# LPC12D27 register map
File version: 3
Registers are 32-bit, read-write, reset 0x0 unless marked. A register's access mark holds for its fields unless they carry their own. Offsets are from the block's base; [hi:lo] are bit positions; {n}, {i} and the like mark numbered series; 'fields as' and 'values as' point back to an identical list.

## IOCON — Product name title=UM10441 Chapter title=LPC122x I/O configuration (IOCONFIG) Modification date=8/18/2011 Major revision=2 Minor revision=0
Base 0x40044000
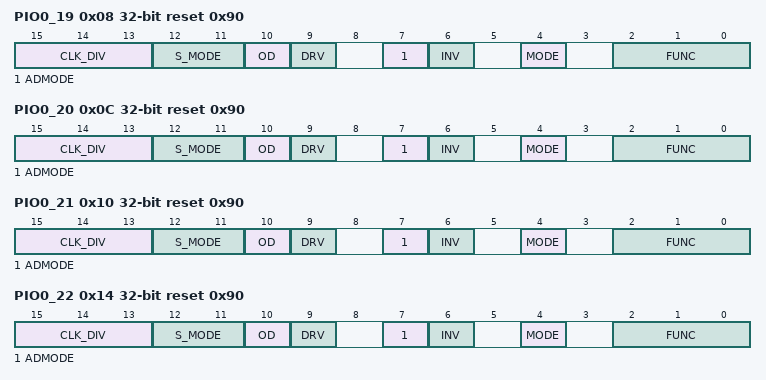
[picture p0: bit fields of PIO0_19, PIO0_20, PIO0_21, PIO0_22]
0x08 PIO0_19 reset 0x90 — Configures pin PIO0_19/ACMP0_I0/CT32B0_1.
  [15:13] CLK_DIV — Select peripheral clock divider for input filter sampling clock.
    {v}=IOCONFIGCLKDIV{v}_ (v=0..6)
  [12:11] S_MODE — Sample mode
    0=BYPASS_INPUT_FILTER_; 1=ONEFILTERCLOCK (Input pulses shorter than one filter clock are rejected.); 2=TWOFILTERCLOCKS (Input pulses shorter than two filter clocks are rejected.); 3=THREEFILTERCLOCKS (Input pulses shorter than three filter clocks are rejected.)
  [10] OD — Open-drain mode.
    0=OPEN_DRAIN_MODE_DISA (Open-drain mode disabled.); 1=OPEN_DRAIN_MODE_ENAB (Open-drain mode enabled.)
  [9] DRV — Drive current mode (Normal-drive pin).
    0=HIGH_MODE_CURRENT_SE (High mode current selected.); 1=LOW_MODE_CURRENT_SEL (Low mode current selected.)
  [7] ADMODE — Analog/Digital mode
    0=ANALOG_MODE_ENABLED_; 1=DIGITAL_MODE_ENABLED
  [6] INV — Invert input
    0=INPUT_NOT_INVERTED_; 1=INPUT_INVERTED_
  [4] MODE — Selects function mode (on-chip pull-up resistor control).
    0=INACTIVE_PULL_UP_RE (Inactive (pull-up resistor not enabled).); 1=PULL_UP_RESISTOR_ENA (Pull-up resistor enabled.)
  [2:0] FUNC — Selects pin function.
    0=SELECTS_FUNCTION_PIO (Selects function PIO0_19.); 1=RESERVED_DO_NOT_USE; 2=ACMP (Select function ACMP0_I0.); 3=CT32 (Select function CT32B0_CAP1.); 4=CT32 (Select function CT32B0_MAT1.)
0x0C PIO0_20 reset 0x90 — Configures pin PIO0_20/ACMP0_I1/CT32B0_2.
  [15:13] CLK_DIV — Select peripheral clock divider for input filter sampling clock.
    {v}=IOCONFIGCLKDIV{v}_ (v=0..6)
  [12:11] S_MODE — Sample mode
    values as PIO0_19.S_MODE
  [10] OD — Open-drain mode.
    values as PIO0_19.OD
  [9] DRV — Drive current mode (Normal-drive pin).
    values as PIO0_19.DRV
  [7] ADMODE — Analog/Digital mode
    0=ANALOG_MODE_ENABLED_; 1=DIGITAL_MODE_ENABLED
  [6] INV — Invert input
    0=INPUT_NOT_INVERTED_; 1=INPUT_INVERTED_
  [4] MODE — Selects function mode (on-chip pull-up resistor control).
    values as PIO0_19.MODE
  [2:0] FUNC — Selects pin function.
    0=SELECTS_FUNCTION_PIO (Selects function PIO0_20.); 1=RESERVED_DO_NOT_USE; 2=ACMP (Select function ACMP0_I1.); 3=CT32 (Select function CT32B0_CAP2.); 4=CT32 (Select function CT32B0_MAT2.)
0x10 PIO0_21 reset 0x90 — Configures pin PIO0_21/ACMP0_I2/CT32B0_3.
  [15:13] CLK_DIV — Select peripheral clock divider for input filter sampling clock.
    {v}=IOCONFIGCLKDIV{v}_ (v=0..6)
  [12:11] S_MODE — Sample mode
    values as PIO0_19.S_MODE
  [10] OD — Open-drain mode.
    values as PIO0_19.OD
  [9] DRV — Drive current mode (Normal-drive pin).
    values as PIO0_19.DRV
  [7] ADMODE — Analog/Digital mode
    0=ANALOG_MODE_ENABLED_; 1=DIGITAL_MODE_ENABLED
  [6] INV — Invert input
    0=INPUT_NOT_INVERTED_; 1=INPUT_INVERTED_
  [4] MODE — Selects function mode (on-chip pull-up resistor control).
    values as PIO0_19.MODE
  [2:0] FUNC — Selects pin function.
    0=SELECTS_FUNCTION_PIO (Selects function PIO0_21.); 1=RESERVED_DO_NOT_USE; 2=ACMP (Select function ACMP0_I2.); 3=CT32 (Select function CT32B0_CAP3.); 4=CT32 (Select function CT32B0_MAT3.)
0x14 PIO0_22 reset 0x90 — Configures pin PIO0_22/ACMP0_I3.
  [15:13] CLK_DIV — Select peripheral clock divider for input filter sampling clock.
    {v}=IOCONFIGCLKDIV{v}_ (v=0..6)
  [12:11] S_MODE — Sample mode
    values as PIO0_19.S_MODE
  [10] OD — Open-drain mode.
    values as PIO0_19.OD
  [9] DRV — Drive current mode (Normal-drive pin).
    values as PIO0_19.DRV
  [7] ADMODE — Analog/Digital mode
    0=ANALOG_MODE_ENABLED_; 1=DIGITAL_MODE_ENABLED
  [6] INV — Invert input
    0=INPUT_NOT_INVERTED_; 1=INPUT_INVERTED_
  [4] MODE — Selects function mode (on-chip pull-up resistor control).
    values as PIO0_19.MODE
  [2:0] FUNC — Selects pin function.
    0=SELECTS_FUNCTION_PIO (Selects function PIO0_22.); 1=RESERVED_DO_NOT_USE; 2=ACMP (Select function ACMP0_I3.)
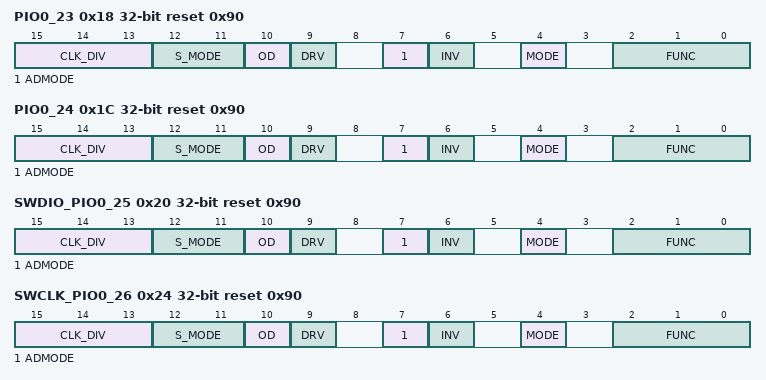
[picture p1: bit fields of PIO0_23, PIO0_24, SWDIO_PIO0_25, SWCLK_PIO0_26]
0x18 PIO0_23 reset 0x90 — Configures pin PIO0_23/ACMP1_I0/CT32B1_0.
  [15:13] CLK_DIV — Select peripheral clock divider for input filter sampling clock.
    {v}=IOCONFIGCLKDIV{v}_ (v=0..6)
  [12:11] S_MODE — Sample mode
    values as PIO0_19.S_MODE
  [10] OD — Open-drain mode.
    values as PIO0_19.OD
  [9] DRV — Drive current mode (Normal-drive pin).
    values as PIO0_19.DRV
  [7] ADMODE — Analog/Digital mode
    0=ANALOG_MODE_ENABLED_; 1=DIGITAL_MODE_ENABLED
  [6] INV — Invert input
    0=INPUT_NOT_INVERTED_; 1=INPUT_INVERTED_
  [4] MODE — Selects function mode (on-chip pull-up resistor control).
    values as PIO0_19.MODE
  [2:0] FUNC — Selects pin function.
    0=SELECTS_FUNCTION_PIO (Selects function PIO0_23.); 1=RESERVED_DO_NOT_USE; 2=ACMP (Select function ACMP1_I0.); 3=CT32 (Select function CT32B1_CAP0.); 4=CT32 (Select function CT32B1_MAT0.)
0x1C PIO0_24 reset 0x90 — Configures pin PIO0_24/ACMP1_I1/CT32B1_1.
  [15:13] CLK_DIV — Select peripheral clock divider for input filter sampling clock.
    {v}=IOCONFIGCLKDIV{v}_ (v=0..6)
  [12:11] S_MODE — Sample mode
    values as PIO0_19.S_MODE
  [10] OD — Open-drain mode.
    values as PIO0_19.OD
  [9] DRV — Drive current mode (Normal-drive pin).
    values as PIO0_19.DRV
  [7] ADMODE — Analog/Digital mode
    0=ANALOG_MODE_ENABLED_; 1=DIGITAL_MODE_ENABLED
  [6] INV — Invert input
    0=INPUT_NOT_INVERTED_; 1=INPUT_INVERTED_
  [4] MODE — Selects function mode (on-chip pull-up resistor control).
    values as PIO0_19.MODE
  [2:0] FUNC — Selects pin function.
    0=SELECTS_FUNCTION_PIO (Selects function PIO0_24.); 1=RESERVED_DO_NOT_USE; 2=ACMP (Select function ACMP1_I1.); 3=CT32 (Select function CT32B1_CAP1.); 4=CT32 (Select function CT32B1_MAT1.)
0x20 SWDIO_PIO0_25 reset 0x90 — Configures pin SWDIO/ACMP1_I2/ CT32B1_2/PIO0_25.
  [15:13] CLK_DIV — Select peripheral clock divider for input filter sampling clock.
    {v}=IOCONFIGCLKDIV{v}_ (v=0..6)
  [12:11] S_MODE — Sample mode
    values as PIO0_19.S_MODE
  [10] OD — Open-drain mode.
    values as PIO0_19.OD
  [9] DRV — Drive current mode (Normal-drive pin).
    values as PIO0_19.DRV
  [7] ADMODE — Analog/Digital mode
    0=ANALOG_MODE_ENABLED_; 1=DIGITAL_MODE_ENABLED
  [6] INV — Invert input
    0=INPUT_NOT_INVERTED_; 1=INPUT_INVERTED_
  [4] MODE — Selects function mode (on-chip pull-up resistor control).
    values as PIO0_19.MODE
  [2:0] FUNC — Selects pin function.
    0=SELECTS_FUNCTION_SWD (Selects function SWDIO.); 1=RESERVED_DO_NOT_USE; 2=ACMP (Select function ACMP1_I2.); 3=CT32 (Select function CT32B1_CAP2.); 4=CT32 (Select function CT32B1_MAT2.); 6=PIO0 (Select function PIO0_25.)
0x24 SWCLK_PIO0_26 reset 0x90 — Configures pin SWCLK/PIO0_26/ACMP1_I3/ CT32B1_3/PIO0_26
  [15:13] CLK_DIV — Select peripheral clock divider for input filter sampling clock.
    {v}=IOCONFIGCLKDIV{v}_ (v=0..6)
  [12:11] S_MODE — Sample mode
    values as PIO0_19.S_MODE
  [10] OD — Open-drain mode.
    values as PIO0_19.OD
  [9] DRV — Drive current mode (Normal-drive pin).
    values as PIO0_19.DRV
  [7] ADMODE — Analog/Digital mode
    0=ANALOG_MODE_ENABLED_; 1=DIGITAL_MODE_ENABLED
  [6] INV — Invert input
    0=INPUT_NOT_INVERTED_; 1=INPUT_INVERTED_
  [4] MODE — Selects function mode (on-chip pull-up resistor control).
    values as PIO0_19.MODE
  [2:0] FUNC — Selects pin function.
    0=SELECTS_FUNCTION_SWC (Selects function SWCLK.); 1=RESERVED_DO_NOT_USE; 2=ACMP (Select function ACMP1_I3.); 3=CT32 (Select function CT32B1_CAP3.); 4=CT32 (Select function CT32B1_MAT3.); 6=PIO0 (Select function PIO0_26.)
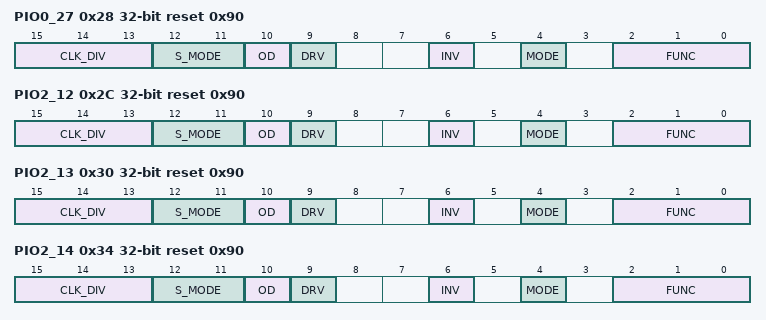
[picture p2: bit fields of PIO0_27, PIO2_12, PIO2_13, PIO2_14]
0x28 PIO0_27 reset 0x90 — Configures pin PIO0_27/ACMP0_O.
  [15:13] CLK_DIV — Select peripheral clock divider for input filter sampling clock.
    {v}=IOCONFIGCLKDIV{v}_ (v=0..6)
  [12:11] S_MODE — Sample mode
    values as PIO0_19.S_MODE
  [10] OD — Open-drain mode.
    values as PIO0_19.OD
  [9] DRV — Drive current mode (High-drive pin).
    0=LOW_MODE_CURRENT_SEL (Low mode current selected.); 1=HIGH_MODE_CURRENT_SE (High mode current selected.)
  [6] INV — Invert input
    0=INPUT_NOT_INVERTED_; 1=INPUT_INVERTED_
  [4] MODE — Selects function mode (on-chip pull-up resistor control).
    values as PIO0_19.MODE
  [2:0] FUNC — Selects pin function.
    0=SELECTS_FUNCTION_PIO (Selects function PIO0_26.); 1=RESERVED_DO_NOT_USE; 2=ACMP (Select function ACMP0_O.)
0x2C PIO2_12 reset 0x90 — Configures pin PIO2_12/RXD1.
  [15:13] CLK_DIV — Select peripheral clock divider for input filter sampling clock.
    {v}=IOCONFIGCLKDIV{v}_ (v=0..6)
  [12:11] S_MODE — Sample mode
    values as PIO0_19.S_MODE
  [10] OD — Open-drain mode.
    values as PIO0_19.OD
  [9] DRV — Drive current mode (Normal-drive pin).
    values as PIO0_27.DRV
  [6] INV — Invert input
    0=INPUT_NOT_INVERTED_; 1=INPUT_INVERTED_
  [4] MODE — Selects function mode (on-chip pull-up resistor control).
    values as PIO0_19.MODE
  [2:0] FUNC — Selects pin function.
    0=SELECTS_FUNCTION_PIO (Selects function PIO2_12.); 1=RESERVED_DO_NOT_USE; 3=SELECTS_FUNCTION_RXD (Selects function RXD1.)
0x30 PIO2_13 reset 0x90 — Configures pin PIO2_13/TXD1.
  [15:13] CLK_DIV — Select peripheral clock divider for input filter sampling clock.
    {v}=IOCONFIGCLKDIV{v}_ (v=0..6)
  [12:11] S_MODE — Sample mode
    values as PIO0_19.S_MODE
  [10] OD — Open-drain mode.
    values as PIO0_19.OD
  [9] DRV — Drive current mode (Normal-drive pin).
    values as PIO0_27.DRV
  [6] INV — Invert input
    0=INPUT_NOT_INVERTED_; 1=INPUT_INVERTED_
  [4] MODE — Selects function mode (on-chip pull-up resistor control).
    values as PIO0_19.MODE
  [2:0] FUNC — Selects pin function.
    0=SELECTS_FUNCTION_PIO (Selects function PIO2_13.); 1=RESERVED_DO_NOT_USE; 3=TXD1 (Select function TXD1.)
0x34 PIO2_14 reset 0x90 — Configures pin PIO2_14.
  [15:13] CLK_DIV — Select peripheral clock divider for input filter sampling clock.
    {v}=IOCONFIGCLKDIV{v}_ (v=0..6)
  [12:11] S_MODE — Sample mode
    values as PIO0_19.S_MODE
  [10] OD — Open-drain mode.
    values as PIO0_19.OD
  [9] DRV — Drive current mode (Normal-drive pin).
    values as PIO0_27.DRV
  [6] INV — Invert input
    0=INPUT_NOT_INVERTED_; 1=INPUT_INVERTED_
  [4] MODE — Selects function mode (on-chip pull-up resistor control).
    values as PIO0_19.MODE
  [2:0] FUNC — Selects pin function.
    0=SELECTS_FUNCTION_PIO (Selects function PIO2_14.)
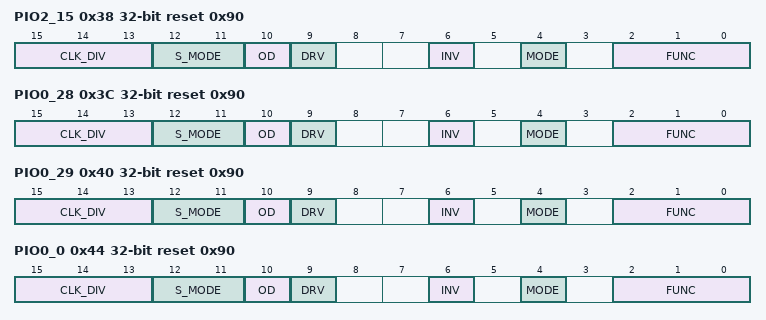
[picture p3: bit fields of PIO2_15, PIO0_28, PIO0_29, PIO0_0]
0x38 PIO2_15 reset 0x90 — Configures pin PIO2_15.
  [15:13] CLK_DIV — Select peripheral clock divider for input filter sampling clock.
    {v}=IOCONFIGCLKDIV{v}_ (v=0..6)
  [12:11] S_MODE — Sample mode
    values as PIO0_19.S_MODE
  [10] OD — Open-drain mode.
    values as PIO0_19.OD
  [9] DRV — Drive current mode (Normal-drive pin).
    values as PIO0_27.DRV
  [6] INV — Invert input
    0=INPUT_NOT_INVERTED_; 1=INPUT_INVERTED_
  [4] MODE — Selects function mode (on-chip pull-up resistor control).
    values as PIO0_19.MODE
  [2:0] FUNC — Selects pin function.
    0=SELECTS_FUNCTION_PIO (Selects function PIO2_15.)
0x3C PIO0_28 reset 0x90 — Configures pin PIO0_28/ACMP1_O/CT16B0_0.
  [15:13] CLK_DIV — Select peripheral clock divider for input filter sampling clock.
    {v}=IOCONFIGCLKDIV{v}_ (v=0..6)
  [12:11] S_MODE — Sample mode
    values as PIO0_19.S_MODE
  [10] OD — Open-drain mode.
    values as PIO0_19.OD
  [9] DRV — Drive current mode (High-drive pin).
    values as PIO0_27.DRV
  [6] INV — Invert input
    0=INPUT_NOT_INVERTED_; 1=INPUT_INVERTED_
  [4] MODE — Selects function mode (on-chip pull-up resistor control).
    values as PIO0_19.MODE
  [2:0] FUNC — Selects pin function.
    0=SELECTS_FUNCTION_PIO (Selects function PIO0_28.); 1=RESERVED_DO_NOT_USE; 2=ACMP (Select function ACMP1_O.); 3=CT16 (Select function CT16B0_CAP0.); 4=CT16 (Select function CT16B0_MAT0.)
0x40 PIO0_29 reset 0x90 — Configures pin PIO0_29/ROSC/CT16B0_1.
  [15:13] CLK_DIV — Select peripheral clock divider for input filter sampling clock.
    {v}=IOCONFIGCLKDIV{v}_ (v=0..6)
  [12:11] S_MODE — Sample mode
    values as PIO0_19.S_MODE
  [10] OD — Open-drain mode.
    values as PIO0_19.OD
  [9] DRV — Drive current mode (High-drive pin).
    values as PIO0_27.DRV
  [6] INV — Invert input
    0=INPUT_NOT_INVERTED_; 1=INPUT_INVERTED_
  [4] MODE — Selects function mode (on-chip pull-up resistor control).
    values as PIO0_19.MODE
  [2:0] FUNC — Selects pin function.
    0=SELECTS_FUNCTION_PIO (Selects function PIO0_29.); 1=RESERVED_DO_NOT_USE; 2=ROSC (Select function ROSC.); 3=CT16 (Select function CT16B0_CAP1.); 4=CT16 (Select function CT16B0_MAT1.)
0x44 PIO0_0 reset 0x90 — Configures pin PIO0_0/ RTS0.
  [15:13] CLK_DIV — Select peripheral clock divider for input filter sampling clock.
    {v}=IOCONFIGCLKDIV{v}_ (v=0..6)
  [12:11] S_MODE — Sample mode
    values as PIO0_19.S_MODE
  [10] OD — Open-drain mode.
    values as PIO0_19.OD
  [9] DRV — Drive current mode (Normal-drive pin).
    values as PIO0_27.DRV
  [6] INV — Invert input
    0=INPUT_NOT_INVERTED_; 1=INPUT_INVERTED_
  [4] MODE — Selects function mode (on-chip pull-up resistor control).
    values as PIO0_19.MODE
  [2:0] FUNC — Selects pin function.
    0=SELECTS_FUNCTION_PIO (Selects function PIO0_0.); 1=RESERVED_DO_NOT_USE; 2=RTS0 (Select function RTS0.)
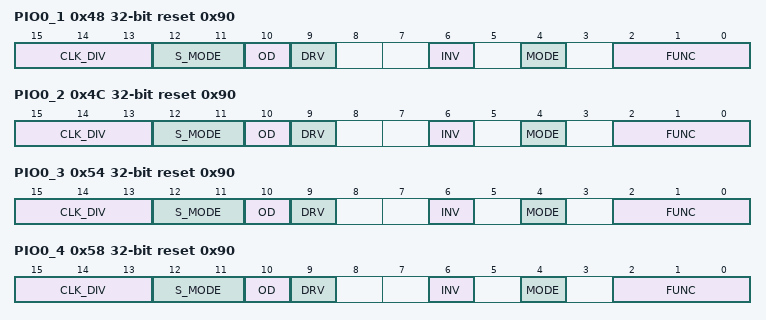
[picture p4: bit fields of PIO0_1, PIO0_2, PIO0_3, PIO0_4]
0x48 PIO0_1 reset 0x90 — Configures pin PIO0_1CT32B0_0/RXD0.
  [15:13] CLK_DIV — Select peripheral clock divider for input filter sampling clock.
    {v}=IOCONFIGCLKDIV{v}_ (v=0..6)
  [12:11] S_MODE — Sample mode
    values as PIO0_19.S_MODE
  [10] OD — Open-drain mode.
    values as PIO0_19.OD
  [9] DRV — Drive current mode (Normal-drive pin).
    values as PIO0_27.DRV
  [6] INV — Invert input
    0=INPUT_NOT_INVERTED_; 1=INPUT_INVERTED_
  [4] MODE — Selects function mode (on-chip pull-up resistor control).
    values as PIO0_19.MODE
  [2:0] FUNC — Selects pin function.
    0=SELECTS_FUNCTION_PIO (Selects function PIO0_1.); 1=RESERVED_DO_NOT_USE; 2=RXD0 (Select function RXD0.); 3=CT32 (Select function CT32B0_CAP0.); 4=CT32 (Select function CT32B0_MAT0.)
0x4C PIO0_2 reset 0x90 — Configures pin PIO0_2/TXD0/CT32B0_1.
  [15:13] CLK_DIV — Select peripheral clock divider for input filter sampling clock.
    {v}=IOCONFIGCLKDIV{v}_ (v=0..6)
  [12:11] S_MODE — Sample mode
    values as PIO0_19.S_MODE
  [10] OD — Open-drain mode.
    values as PIO0_19.OD
  [9] DRV — Drive current mode (Normal-drive pin).
    values as PIO0_27.DRV
  [6] INV — Invert input
    0=INPUT_NOT_INVERTED_; 1=INPUT_INVERTED_
  [4] MODE — Selects function mode (on-chip pull-up resistor control).
    values as PIO0_19.MODE
  [2:0] FUNC — Selects pin function.
    0=SELECTS_FUNCTION_PIO (Selects function PIO0_2.); 1=RESERVED_DO_NOT_USE; 2=TXD0 (Select function TXD0.); 3=CT32 (Select function CT32B0_CAP1.); 4=CT32 (Select function CT32B0_MAT1.)
0x54 PIO0_3 reset 0x90 — Configures pin PIO0_3/DTR0/CT32B0_2.
  [15:13] CLK_DIV — Select peripheral clock divider for input filter sampling clock.
    {v}=IOCONFIGCLKDIV{v}_ (v=0..6)
  [12:11] S_MODE — Sample mode
    values as PIO0_19.S_MODE
  [10] OD — Open-drain mode.
    values as PIO0_19.OD
  [9] DRV — Drive current mode (Normal-drive pin).
    values as PIO0_27.DRV
  [6] INV — Invert input
    0=INPUT_NOT_INVERTED_; 1=INPUT_INVERTED_
  [4] MODE — Selects function mode (on-chip pull-up resistor control).
    values as PIO0_19.MODE
  [2:0] FUNC — Selects pin function.
    0=SELECTS_FUNCTION_PIO (Selects function PIO0_3.); 1=RESERVED_DO_NOT_USE; 2=DTR0 (Select function DTR0.); 3=CT32 (Select function CT32B0_CAP2.); 4=CT32 (Select function CT32B0_MAT2.)
0x58 PIO0_4 reset 0x90 — Configures pin PIO0_4/ DSR0/CT32B0_3.
  [15:13] CLK_DIV — Select peripheral clock divider for input filter sampling clock.
    {v}=IOCONFIGCLKDIV{v}_ (v=0..6)
  [12:11] S_MODE — Sample mode
    values as PIO0_19.S_MODE
  [10] OD — Open-drain mode.
    values as PIO0_19.OD
  [9] DRV — Drive current mode (Normal-drive pin).
    values as PIO0_27.DRV
  [6] INV — Invert input
    0=INPUT_NOT_INVERTED_; 1=INPUT_INVERTED_
  [4] MODE — Selects function mode (on-chip pull-up resistor control).
    values as PIO0_19.MODE
  [2:0] FUNC — Selects pin function.
    0=SELECTS_FUNCTION_PIO (Selects function PIO0_4.); 1=RESERVED_DO_NOT_USE; 2=DSR0 (Select function DSR0.); 3=CT32 (Select function CT32B0_CAP3.); 4=CT32 (Select function CT32B0_MAT3.)
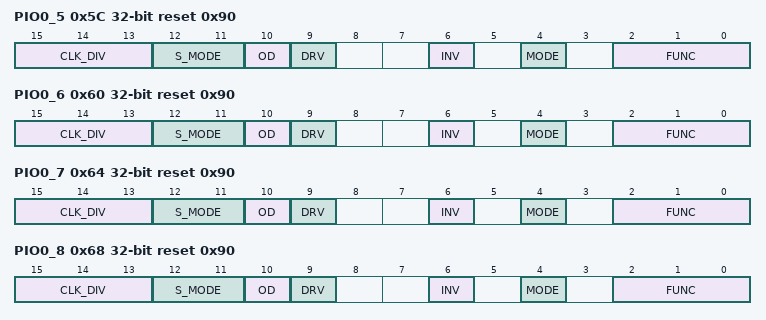
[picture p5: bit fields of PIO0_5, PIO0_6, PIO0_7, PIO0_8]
0x5C PIO0_5 reset 0x90 — Configures pin PIO0_5.
  [15:13] CLK_DIV — Select peripheral clock divider for input filter sampling clock.
    {v}=IOCONFIGCLKDIV{v}_ (v=0..6)
  [12:11] S_MODE — Sample mode
    0=BYPASS_INPUT_FILTER_; 1=INPUT_PULSES_SHORTER (Input pulses shorter than one filter clock are rejected.); 2=INPUT_PULSES_SHORTER (Input pulses shorter than two filter clocks are rejected.); 3=INPUT_PULSES_SHORTER (Input pulses shorter than three filter clocks are rejected.)
  [10] OD — Open-drain mode.
    0=ONEFILTERCLOCK (Open-drain mode disabled.); 1=TWOFILTERCLOCKS (Open-drain mode enabled.)
  [9] DRV — Drive current mode (Normal-drive pin).
    values as PIO0_27.DRV
  [6] INV — Invert input
    0=INPUT_NOT_INVERTED_; 1=INPUT_INVERTED_
  [4] MODE — Selects function mode (on-chip pull-up resistor control).
    values as PIO0_19.MODE
  [2:0] FUNC — Selects pin function.
    0=SELECTS_FUNCTION_PIO (Selects function PIO0_5.); 1=RESERVED_DO_NOT_USE; 2=DCD0 (Select function DCD0.)
0x60 PIO0_6 reset 0x90 — Configures pin PIO0_6/RI0/CT32B1_0.
  [15:13] CLK_DIV — Select peripheral clock divider for input filter sampling clock.
    {v}=IOCONFIGCLKDIV{v}_ (v=0..6)
  [12:11] S_MODE — Sample mode
    values as PIO0_19.S_MODE
  [10] OD — Open-drain mode.
    values as PIO0_19.OD
  [9] DRV — Drive current mode (Normal-drive pin).
    values as PIO0_27.DRV
  [6] INV — Invert input
    0=INPUT_NOT_INVERTED_; 1=INPUT_INVERTED_
  [4] MODE — Selects function mode (on-chip pull-up resistor control).
    values as PIO0_19.MODE
  [2:0] FUNC — Selects pin function.
    0=SELECTS_FUNCTION_PIO (Selects function PIO0_6.); 1=RESERVED_DO_NOT_USE; 2=RI0_ (Select function RI0.); 3=CT32 (Select function CT32B1_CAP0.); 4=CT32 (Select function CT32B1_MAT0.)
0x64 PIO0_7 reset 0x90 — Configures pin PIO0_7CTS0/CT32B1_1.
  [15:13] CLK_DIV — Select peripheral clock divider for input filter sampling clock.
    {v}=IOCONFIGCLKDIV{v}_ (v=0..6)
  [12:11] S_MODE — Sample mode
    values as PIO0_19.S_MODE
  [10] OD — Open-drain mode.
    values as PIO0_19.OD
  [9] DRV — Drive current mode (Normal-drive pin).
    values as PIO0_27.DRV
  [6] INV — Invert input
    0=INPUT_NOT_INVERTED_; 1=INPUT_INVERTED_
  [4] MODE — Selects function mode (on-chip pull-up resistor control).
    values as PIO0_19.MODE
  [2:0] FUNC — Selects pin function.
    0=SELECTS_FUNCTION_PIO (Selects function PIO0_7.); 1=RESERVED_DO_NOT_USE; 2=CTS0 (Select function CTS0.); 3=CT32 (Select function CT32B1_CAP1.); 4=CT32 (Select function CT32B1_MAT1.)
0x68 PIO0_8 reset 0x90 — Configures pin PIO0_8/RXD1/CT32B1_2.
  [15:13] CLK_DIV — Select peripheral clock divider for input filter sampling clock.
    {v}=IOCONFIGCLKDIV{v}_ (v=0..6)
  [12:11] S_MODE — Sample mode
    values as PIO0_19.S_MODE
  [10] OD — Open-drain mode.
    values as PIO0_19.OD
  [9] DRV — Drive current mode (Normal-drive pin).
    values as PIO0_27.DRV
  [6] INV — Invert input
    0=INPUT_NOT_INVERTED_; 1=INPUT_INVERTED_
  [4] MODE — Selects function mode (on-chip pull-up resistor control).
    values as PIO0_19.MODE
  [2:0] FUNC — Selects pin function.
    0=SELECTS_FUNCTION_PIO (Selects function PIO0_8.); 1=RESERVED_DO_NOT_USE; 2=RXD1 (Select function RXD1.); 3=CT32 (Select function CT32B1_CAP2.); 4=CT32 (Select function CT32B1_MAT2.)
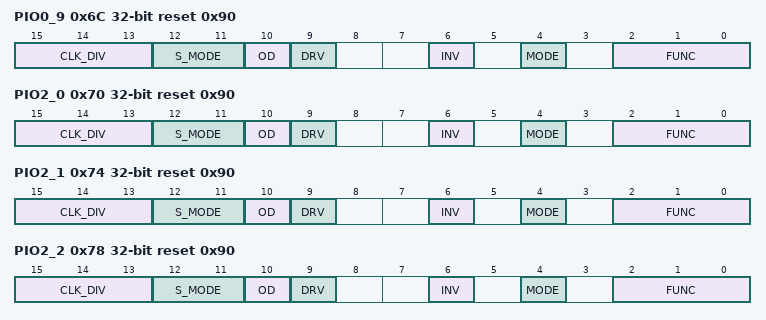
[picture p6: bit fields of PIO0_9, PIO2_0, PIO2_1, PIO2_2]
0x6C PIO0_9 reset 0x90 — Configures pin PIO0_9/TXD1/CT32B1_3.
  [15:13] CLK_DIV — Select peripheral clock divider for input filter sampling clock.
    {v}=IOCONFIGCLKDIV{v}_ (v=0..6)
  [12:11] S_MODE — Sample mode
    values as PIO0_19.S_MODE
  [10] OD — Open-drain mode.
    values as PIO0_19.OD
  [9] DRV — Drive current mode (Normal-drive pin).
    values as PIO0_27.DRV
  [6] INV — Invert input
    0=INPUT_NOT_INVERTED_; 1=INPUT_INVERTED_
  [4] MODE — Selects function mode (on-chip pull-up resistor control).
    values as PIO0_19.MODE
  [2:0] FUNC — Selects pin function.
    0=SELECTS_FUNCTION_PIO (Selects function PIO0_9.); 1=RESERVED_DO_NOT_USE; 2=TXD1 (Select function TXD1.); 3=CT32 (Select function CT32B1_CAP3.); 4=CT32 (Select function CT32B1_MAT3.)
0x70 PIO2_0 reset 0x90 — Configures pin PIO2_0/CT16B0_0/ RTS0.
  [15:13] CLK_DIV — Select peripheral clock divider for input filter sampling clock.
    {v}=IOCONFIGCLKDIV{v}_ (v=0..6)
  [12:11] S_MODE — Sample mode
    values as PIO0_19.S_MODE
  [10] OD — Open-drain mode.
    values as PIO0_19.OD
  [9] DRV — Drive current mode (Normal-drive pin).
    values as PIO0_27.DRV
  [6] INV — Invert input
    0=INPUT_NOT_INVERTED_; 1=INPUT_INVERTED_
  [4] MODE — Selects function mode (on-chip pull-up resistor control).
    values as PIO0_19.MODE
  [2:0] FUNC — Selects pin function.
    0=SELECTS_FUNCTION_PIO (Selects function PIO2_0.); 2=RESERVED_DO_NOT_USE; 3=CT16 (Select function CT16B0_CAP0.); 4=CT16 (Select function CT16B0_MAT0.); 5=RTS0 (Select function RTS0.)
0x74 PIO2_1 reset 0x90 — Configures pin PIO2_1/CT16B0_1/RXD0.
  [15:13] CLK_DIV — Select peripheral clock divider for input filter sampling clock.
    {v}=IOCONFIGCLKDIV{v}_ (v=0..6)
  [12:11] S_MODE — Sample mode
    values as PIO0_19.S_MODE
  [10] OD — Open-drain mode.
    values as PIO0_19.OD
  [9] DRV — Drive current mode (Normal-drive pin).
    values as PIO0_27.DRV
  [6] INV — Invert input
    0=INPUT_NOT_INVERTED_; 1=INPUT_INVERTED_
  [4] MODE — Selects function mode (on-chip pull-up resistor control).
    values as PIO0_19.MODE
  [2:0] FUNC — Selects pin function.
    0=SELECTS_FUNCTION_PIO (Selects function PIO2_1.); 1=RESERVED_DO_NOT_USE; 2=CT16 (Select function CT16B0_CAP1.); 3=CT16 (Select function CT16B0_MAT1.); 4=RXD0 (Select function RXD0.)
0x78 PIO2_2 reset 0x90 — Configures pin PIO2_2/CT16B1_0/TXD0.
  [15:13] CLK_DIV — Select peripheral clock divider for input filter sampling clock.
    {v}=IOCONFIGCLKDIV{v}_ (v=0..6)
  [12:11] S_MODE — Sample mode
    values as PIO0_19.S_MODE
  [10] OD — Open-drain mode.
    values as PIO0_19.OD
  [9] DRV — Drive current mode (Normal-drive pin).
    values as PIO0_27.DRV
  [6] INV — Invert input
    0=INPUT_NOT_INVERTED_; 1=INPUT_INVERTED_
  [4] MODE — Selects function mode (on-chip pull-up resistor control).
    values as PIO0_19.MODE
  [2:0] FUNC — Selects pin function.
    0=SELECTS_FUNCTION_PIO (Selects function PIO2_2.); 1=RESERVED_DO_NOT_USE; 2=CT16 (Select function CT16B1_CAP0.); 3=CT16 (Select function CT16B1_MAT0.); 4=TXD0 (Select function TXD0.)
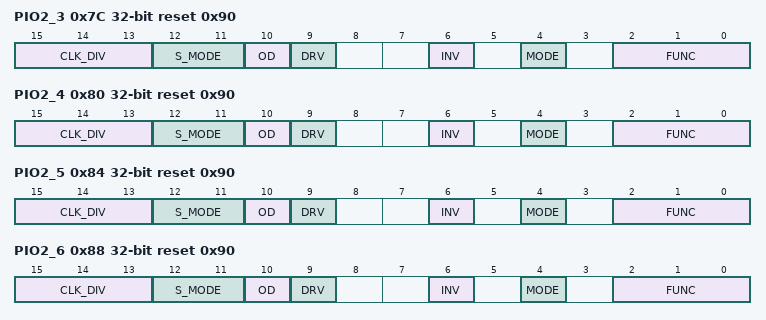
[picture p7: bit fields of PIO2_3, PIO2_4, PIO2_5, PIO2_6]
0x7C PIO2_3 reset 0x90 — Configures pin PIO2_3/CT16B1_1/DTR0.
  [15:13] CLK_DIV — Select peripheral clock divider for input filter sampling clock.
    {v}=IOCONFIGCLKDIV{v}_ (v=0..6)
  [12:11] S_MODE — Sample mode
    values as PIO0_19.S_MODE
  [10] OD — Open-drain mode.
    values as PIO0_19.OD
  [9] DRV — Drive current mode (Normal-drive pin).
    values as PIO0_27.DRV
  [6] INV — Invert input
    0=INPUT_NOT_INVERTED_; 1=INPUT_INVERTED_
  [4] MODE — Selects function mode (on-chip pull-up resistor control).
    values as PIO0_19.MODE
  [2:0] FUNC — Selects pin function.
    0=SELECTS_FUNCTION_PIO (Selects function PIO2_3.); 1=RESERVED_DO_NOT_USE; 2=CT16 (Select function CT16B1_CAP1.); 3=CT16 (Select function CT16B1_MAT1.); 4=DTR0 (Select function DTR0.)
0x80 PIO2_4 reset 0x90 — Configures pin PIO2_4/CT32B0_0/CTS0.
  [15:13] CLK_DIV — Select peripheral clock divider for input filter sampling clock.
    {v}=IOCONFIGCLKDIV{v}_ (v=0..6)
  [12:11] S_MODE — Sample mode
    values as PIO0_19.S_MODE
  [10] OD — Open-drain mode.
    values as PIO0_19.OD
  [9] DRV — Drive current mode (Normal-drive pin).
    values as PIO0_27.DRV
  [6] INV — Invert input
    0=INPUT_NOT_INVERTED_; 1=INPUT_INVERTED_
  [4] MODE — Selects function mode (on-chip pull-up resistor control).
    values as PIO0_19.MODE
  [2:0] FUNC — Selects pin function.
    0=SELECTS_FUNCTION_PIO (Selects function PIO2_4.); 1=RESERVED_DO_NOT_USE; 2=CT32 (Select function CT32B0_CAP0.); 3=CT32 (Select function CT32B0_MAT0.); 4=CTS0 (Select function CTS0.)
0x84 PIO2_5 reset 0x90 — Configures pin PIO2_5/CT32B0_1/ DCD0.
  [15:13] CLK_DIV — Select peripheral clock divider for input filter sampling clock.
    {v}=IOCONFIGCLKDIV{v}_ (v=0..6)
  [12:11] S_MODE — Sample mode
    values as PIO0_19.S_MODE
  [10] OD — Open-drain mode.
    values as PIO0_19.OD
  [9] DRV — Drive current mode (Normal-drive pin).
    values as PIO0_27.DRV
  [6] INV — Invert input
    0=INPUT_NOT_INVERTED_; 1=INPUT_INVERTED_
  [4] MODE — Selects function mode (on-chip pull-up resistor control).
    values as PIO0_19.MODE
  [2:0] FUNC — Selects pin function.
    0=SELECTS_FUNCTION_PIO (Selects function PIO2_5.); 1=RESERVED_DO_NOT_USE; 2=CT32 (Select function CT32B0_CAP1.); 3=CT32 (Select function CT32B0_MAT1.); 4=RI0_ (Select function RI0.)
0x88 PIO2_6 reset 0x90 — Configures pin PIO2_6/CT32B0_2/RI0.
  [15:13] CLK_DIV — Select peripheral clock divider for input filter sampling clock.
    {v}=IOCONFIGCLKDIV{v}_ (v=0..6)
  [12:11] S_MODE — Sample mode
    values as PIO0_19.S_MODE
  [10] OD — Open-drain mode.
    values as PIO0_19.OD
  [9] DRV — Drive current mode (Normal-drive pin).
    values as PIO0_27.DRV
  [6] INV — Invert input
    0=INPUT_NOT_INVERTED_; 1=INPUT_INVERTED_
  [4] MODE — Selects function mode (on-chip pull-up resistor control).
    values as PIO0_19.MODE
  [2:0] FUNC — Selects pin function.
    0=SELECTS_FUNCTION_PIO (Selects function PIO2_6.); 1=RESERVED_DO_NOT_USE; 2=CT32 (Select function CT32B0_CAP2.); 3=CT32 (Select function CT32B0_MAT2.); 4=DCD0 (Select function DCD0.)
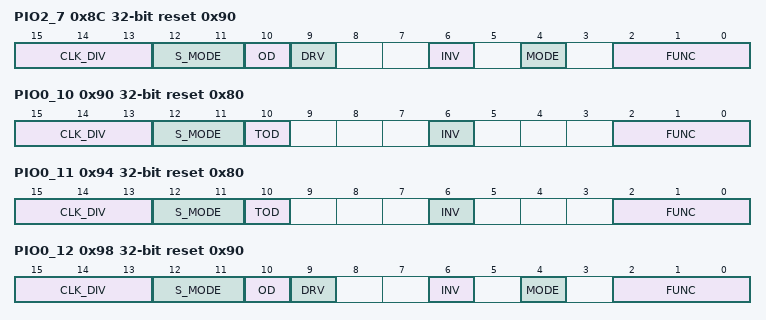
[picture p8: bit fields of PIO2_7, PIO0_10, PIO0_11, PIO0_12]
0x8C PIO2_7 reset 0x90 — Configures pin PIO2_7/CT32B0_3/DSR0.
  [15:13] CLK_DIV — Select peripheral clock divider for input filter sampling clock.
    {v}=IOCONFIGCLKDIV{v}_ (v=0..6)
  [12:11] S_MODE — Sample mode
    values as PIO0_19.S_MODE
  [10] OD — Open-drain mode.
    values as PIO0_19.OD
  [9] DRV — Drive current mode (Normal-drive pin).
    values as PIO0_27.DRV
  [6] INV — Invert input
    0=INPUT_NOT_INVERTED_; 1=INPUT_INVERTED_
  [4] MODE — Selects function mode (on-chip pull-up resistor control).
    values as PIO0_19.MODE
  [2:0] FUNC — Selects pin function.
    0=SELECTS_FUNCTION_PIO (Selects function PIO2_7.); 1=RESERVED_DO_NOT_USE; 2=CT32 (Select function CT32B0_CAP3.); 3=CT32 (Select function CT32B0_MAT3.); 4=DSR0 (Select function DSR0.)
0x90 PIO0_10 reset 0x80 — Configures pin PIO0_10/SCL.
  [15:13] CLK_DIV — Select peripheral clock divider for input filter sampling clock.
    {v}=IOCONFIGCLKDIV{v}_ (v=0..6)
  [12:11] S_MODE — Sample mode
    values as PIO0_19.S_MODE
  [10] TOD — True open-drain mode.
    0=DISABLE_; 1=TRUE_OPEN_DRAIN_MODE (True open-drain mode enabled.)
  [6] INV — Invert input
    0=INPUT_NOT_INVERTED_; 1=INPUT_INVERTED_
  [2:0] FUNC — Selects pin function.
    0=SELECTS_FUNCTION_PIO (Selects function PIO0_10.); 1=RESERVED_DO_NOT_USE; 2=SELECT_I2C_BUS_FUNCT (Select I2C-bus function SCL.)
0x94 PIO0_11 reset 0x80 — Configures pin PIO0_11/SDA/CT16B0_0.
  [15:13] CLK_DIV — Select peripheral clock divider for input filter sampling clock.
    {v}=IOCONFIGCLKDIV{v}_ (v=0..6)
  [12:11] S_MODE — Sample mode
    values as PIO0_19.S_MODE
  [10] TOD — True open-drain mode.
    values as PIO0_10.TOD
  [6] INV — Invert input
    0=INPUT_NOT_INVERTED_; 1=INPUT_INVERTED_
  [2:0] FUNC — Selects pin function.
    0=SELECTS_FUNCTION_PIO (Selects function PIO0_11.); 1=RESERVED_DO_NOT_USE; 2=SELECT_I2C_BUS_FUNCT (Select I2C-bus function SDA.); 3=CT16 (Select function CT16B0_CAP0.); 4=CT16 (Select function CT16B0_MAT0.)
0x98 PIO0_12 reset 0x90 — Configures pin PIO0_12/CLKOUT/CT16B0_1.
  [15:13] CLK_DIV — Select peripheral clock divider for input filter sampling clock.
    {v}=IOCONFIGCLKDIV{v}_ (v=0..6)
  [12:11] S_MODE — Sample mode
    values as PIO0_19.S_MODE
  [10] OD — Open-drain mode.
    values as PIO0_19.OD
  [9] DRV — Drive current mode (High-drive pin).
    values as PIO0_27.DRV
  [6] INV — Invert input
    0=INPUT_NOT_INVERTED_; 1=INPUT_INVERTED_
  [4] MODE — Selects function mode (on-chip pull-up resistor control).
    values as PIO0_19.MODE
  [2:0] FUNC — Selects pin function.
    0=SELECTS_FUNCTION_PIO (Selects function PIO0_12.); 1=RESERVED_DO_NOT_USE; 2=CLKO (Select function CLKOUT.); 3=CT16 (Select function CT16B0_CAP1.); 4=CT16 (Select function CT16B0_MAT1.)
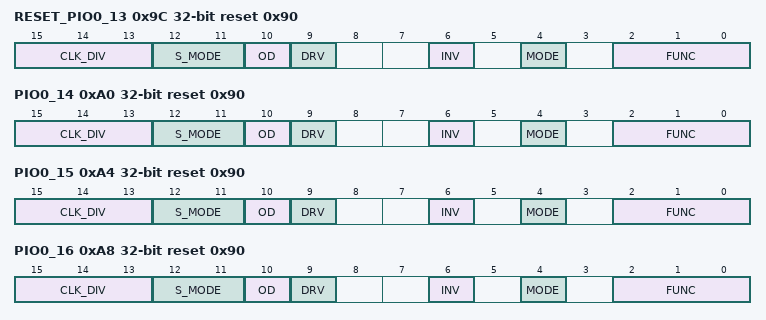
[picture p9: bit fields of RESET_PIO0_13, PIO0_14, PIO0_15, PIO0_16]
0x9C RESET_PIO0_13 reset 0x90 — Configures pin RESET/PIO0_13.
  [15:13] CLK_DIV — Select peripheral clock divider for input filter sampling clock.
    {v}=IOCONFIGCLKDIV{v}_ (v=0..6)
  [12:11] S_MODE — Sample mode
    values as PIO0_19.S_MODE
  [10] OD — Open-drain mode.
    values as PIO0_19.OD
  [9] DRV — Drive current mode (Normal-drive pin).
    values as PIO0_27.DRV
  [6] INV — Invert input
    0=INPUT_NOT_INVERTED_; 1=INPUT_INVERTED_
  [4] MODE — Selects function mode (on-chip pull-up resistor control).
    values as PIO0_19.MODE
  [2:0] FUNC — Selects pin function.
    0=SELECTS_FUNCTION_RES (Selects function RESET.); 1=PIO0 (Select function PIO0_13.); 2=RESERVED_DO_NOT_USE
0xA0 PIO0_14 reset 0x90 — Configures pin PIO0_14/SSP_CLK.
  [15:13] CLK_DIV — Select peripheral clock divider for input filter sampling clock.
    {v}=IOCONFIGCLKDIV{v}_ (v=0..6)
  [12:11] S_MODE — Sample mode
    values as PIO0_19.S_MODE
  [10] OD — Open-drain mode.
    values as PIO0_19.OD
  [9] DRV — Drive current mode (Normal-drive pin).
    values as PIO0_27.DRV
  [6] INV — Invert input
    0=INPUT_NOT_INVERTED_; 1=INPUT_INVERTED_
  [4] MODE — Selects function mode (on-chip pull-up resistor control).
    values as PIO0_19.MODE
  [2:0] FUNC — Selects pin function.
    0=SELECTS_FUNCTION_PIO (Selects function PIO0_14.); 1=RESERVED_DO_NOT_USE; 2=SCK_ (Select function SCK.)
0xA4 PIO0_15 reset 0x90 — Configures pin PIO0_15/SSP_SSEL/CT16B1_0.
  [15:13] CLK_DIV — Select peripheral clock divider for input filter sampling clock.
    {v}=IOCONFIGCLKDIV{v}_ (v=0..6)
  [12:11] S_MODE — Sample mode
    values as PIO0_19.S_MODE
  [10] OD — Open-drain mode.
    values as PIO0_19.OD
  [9] DRV — Drive current mode (Normal-drive pin).
    values as PIO0_27.DRV
  [6] INV — Invert input
    0=INPUT_NOT_INVERTED_; 1=INPUT_INVERTED_
  [4] MODE — Selects function mode (on-chip pull-up resistor control).
    values as PIO0_19.MODE
  [2:0] FUNC — Selects pin function.
    0=SELECTS_FUNCTION_PIO (Selects function PIO0_15.); 1=RESERVED_DO_NOT_USE; 2=SSEL (Select function SSEL.); 3=CT16 (Select function CT16B1_CAP0.); 4=CT16 (Select function CT16B1_MAT0.)
0xA8 PIO0_16 reset 0x90 — Configures pin PIO0_16/SSP_MISO/CT16B1_1.
  [15:13] CLK_DIV — Select peripheral clock divider for input filter sampling clock.
    {v}=IOCONFIGCLKDIV{v}_ (v=0..6)
  [12:11] S_MODE — Sample mode
    values as PIO0_19.S_MODE
  [10] OD — Open-drain mode.
    values as PIO0_19.OD
  [9] DRV — Drive current mode (Normal-drive pin).
    values as PIO0_27.DRV
  [6] INV — Invert input
    0=INPUT_NOT_INVERTED_; 1=INPUT_INVERTED_
  [4] MODE — Selects function mode (on-chip pull-up resistor control).
    values as PIO0_19.MODE
  [2:0] FUNC — Selects pin function.
    0=SELECTS_FUNCTION_PIO (Selects function PIO0_16.); 1=RESERVED_DO_NOT_USE; 2=MISO (Select function MISO.); 3=CT16 (Select function CT16B1_CAP1.); 4=CT16 (Select function CT16B1_MAT1.)
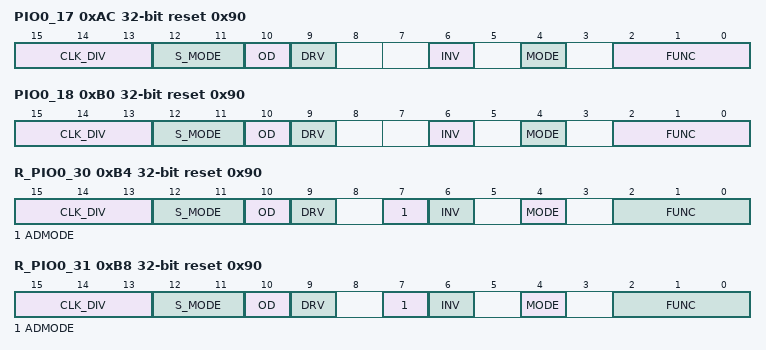
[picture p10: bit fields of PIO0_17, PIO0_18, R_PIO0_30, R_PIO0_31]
0xAC PIO0_17 reset 0x90 — Configures pin PIO0_17/SSP_MOSI.
  [15:13] CLK_DIV — Select peripheral clock divider for input filter sampling clock.
    {v}=IOCONFIGCLKDIV{v}_ (v=0..6)
  [12:11] S_MODE — Sample mode
    values as PIO0_19.S_MODE
  [10] OD — Open-drain mode.
    values as PIO0_19.OD
  [9] DRV — Drive current mode (Normal-drive pin).
    values as PIO0_27.DRV
  [6] INV — Invert input
    0=INPUT_NOT_INVERTED_; 1=INPUT_INVERTED_
  [4] MODE — Selects function mode (on-chip pull-up resistor control).
    values as PIO0_19.MODE
  [2:0] FUNC — Selects pin function.
    0=SELECTS_FUNCTION_PIO (Selects function PIO0_17.); 1=RESERVED_DO_NOT_USE; 2=MOSI (Select function MOSI.)
0xB0 PIO0_18 reset 0x90 — Configures pin PIO0_18/SWCLK/CT32B0_0.
  [15:13] CLK_DIV — Select peripheral clock divider for input filter sampling clock.
    {v}=IOCONFIGCLKDIV{v}_ (v=0..6)
  [12:11] S_MODE — Sample mode
    values as PIO0_19.S_MODE
  [10] OD — Open-drain mode.
    values as PIO0_19.OD
  [9] DRV — Drive current mode (Normal-drive pin).
    values as PIO0_27.DRV
  [6] INV — Invert input
    0=INPUT_NOT_INVERTED_; 1=INPUT_INVERTED_
  [4] MODE — Selects function mode (on-chip pull-up resistor control).
    values as PIO0_19.MODE
  [2:0] FUNC — Selects pin function.
    0=SELECTS_FUNCTION_PIO (Selects function PIO0_18.); 1=SWCL (Select function SWCLK.); 2=RESERVED_DO_NOT_USE; 3=CT32 (Select function CT32B0_CAP0.); 4=CT32 (Select function CT32B0_MAT0.)
0xB4 R_PIO0_30 reset 0x90 — Configures pin R/PIO0_30/AD0.
  [15:13] CLK_DIV — Select peripheral clock divider for input filter sampling clock.
    {v}=IOCONFIGCLKDIV{v}_ (v=0..6)
  [12:11] S_MODE — Sample mode
    values as PIO0_19.S_MODE
  [10] OD — Open-drain mode.
    values as PIO0_19.OD
  [9] DRV — Drive current mode (Normal-drive pin).
    values as PIO0_27.DRV
  [7] ADMODE — Analog/Digital mode
    0=ANALOG_MODE_ENABLED_; 1=DIGITAL_MODE_ENABLED
  [6] INV — Invert input
    0=INPUT_NOT_INVERTED_; 1=INPUT_INVERTED_
  [4] MODE — Selects function mode (on-chip pull-up resistor control).
    values as PIO0_19.MODE
  [2:0] FUNC — Selects pin function.
    1=PIO0 (Select function PIO0_30.); 2=RESERVED_DO_NOT_USE; 3=AD0_ (Select function AD0.)
0xB8 R_PIO0_31 reset 0x90 — Configures pin R/PIO0_31/AD1.
  [15:13] CLK_DIV — Select peripheral clock divider for input filter sampling clock.
    {v}=IOCONFIGCLKDIV{v}_ (v=0..6)
  [12:11] S_MODE — Sample mode
    values as PIO0_19.S_MODE
  [10] OD — Open-drain mode.
    values as PIO0_19.OD
  [9] DRV — Drive current mode (Normal-drive pin).
    values as PIO0_27.DRV
  [7] ADMODE — Analog/Digital mode
    0=ANALOG_MODE_ENABLED_; 1=DIGITAL_MODE_ENABLED
  [6] INV — Invert input
    0=INPUT_NOT_INVERTED_; 1=INPUT_INVERTED_
  [4] MODE — Selects function mode (on-chip pull-up resistor control).
    values as PIO0_19.MODE
  [2:0] FUNC — Selects pin function.
    1=PIO0 (Select function PIO0_31.); 2=RESERVED_DO_NOT_USE; 3=AD1_ (Select function AD1.)
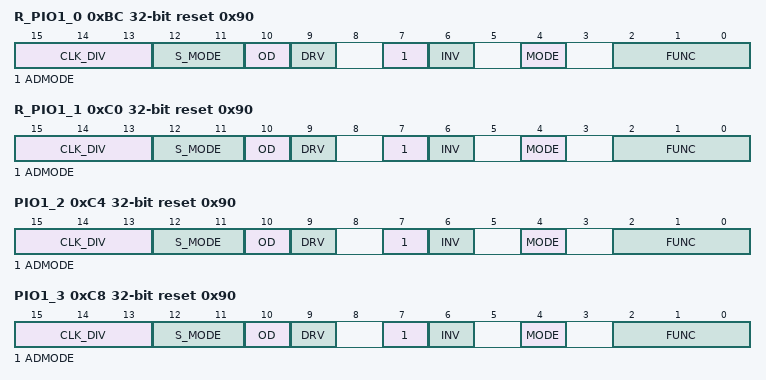
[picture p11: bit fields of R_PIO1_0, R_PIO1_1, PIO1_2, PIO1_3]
0xBC R_PIO1_0 reset 0x90 — Configures pin R/PIO1_0/AD2.
  [15:13] CLK_DIV — Select peripheral clock divider for input filter sampling clock.
    {v}=IOCONFIGCLKDIV{v}_ (v=0..6)
  [12:11] S_MODE — Sample mode
    values as PIO0_19.S_MODE
  [10] OD — Open-drain mode.
    values as PIO0_19.OD
  [9] DRV — Drive current mode (Normal-drive pin).
    values as PIO0_27.DRV
  [7] ADMODE — Analog/Digital mode
    0=ANALOG_MODE_ENABLED_; 1=DIGITAL_MODE_ENABLED
  [6] INV — Invert input
    0=INPUT_NOT_INVERTED_; 1=INPUT_INVERTED_
  [4] MODE — Selects function mode (on-chip pull-up resistor control).
    values as PIO0_19.MODE
  [2:0] FUNC — Selects pin function.
    1=PIO1 (Select function PIO1_0.); 2=AD2_ (Select function AD2.)
0xC0 R_PIO1_1 reset 0x90 — Configures pin R/PIO1_1/AD3.
  [15:13] CLK_DIV — Select peripheral clock divider for input filter sampling clock.
    {v}=IOCONFIGCLKDIV{v}_ (v=0..6)
  [12:11] S_MODE — Sample mode
    values as PIO0_19.S_MODE
  [10] OD — Open-drain mode.
    values as PIO0_19.OD
  [9] DRV — Drive current mode (Normal-drive pin).
    values as PIO0_27.DRV
  [7] ADMODE — Analog/Digital mode
    0=ANALOG_MODE_ENABLED_; 1=DIGITAL_MODE_ENABLED
  [6] INV — Invert input
    0=INPUT_NOT_INVERTED_; 1=INPUT_INVERTED_
  [4] MODE — Selects function mode (on-chip pull-up resistor control).
    values as PIO0_19.MODE
  [2:0] FUNC — Selects pin function.
    1=PIO1 (Select function PIO1_0.); 2=AD3_ (Select function AD3.)
0xC4 PIO1_2 reset 0x90 — Configures pin PIO1_2/SWDIO/AD4.
  [15:13] CLK_DIV — Select peripheral clock divider for input filter sampling clock.
    {v}=IOCONFIGCLKDIV{v}_ (v=0..6)
  [12:11] S_MODE — Sample mode
    values as PIO0_19.S_MODE
  [10] OD — Open-drain mode.
    values as PIO0_19.OD
  [9] DRV — Drive current mode (Normal-drive pin).
    values as PIO0_27.DRV
  [7] ADMODE — Analog/Digital mode
    0=ANALOG_MODE_ENABLED_; 1=DIGITAL_MODE_ENABLED
  [6] INV — Invert input
    0=INPUT_NOT_INVERTED_; 1=INPUT_INVERTED_
  [4] MODE — Selects function mode (on-chip pull-up resistor control).
    values as PIO0_19.MODE
  [2:0] FUNC — Selects pin function.
    0=SELECTS_FUNCTION_PIO (Selects function PIO1_2.); 1=SWDI (Select function SWDIO.); 2=AD4_ (Select function AD4.)
0xC8 PIO1_3 reset 0x90 — Configures pin PIO1_3/AD5/WAKEUP.
  [15:13] CLK_DIV — Select peripheral clock divider for input filter sampling clock.
    {v}=IOCONFIGCLKDIV{v}_ (v=0..6)
  [12:11] S_MODE — Sample mode
    values as PIO0_19.S_MODE
  [10] OD — Open-drain mode.
    values as PIO0_19.OD
  [9] DRV — Drive current mode (Normal-drive pin).
    values as PIO0_27.DRV
  [7] ADMODE — Analog/Digital mode
    0=ANALOG_MODE_ENABLED_; 1=DIGITAL_MODE_ENABLED
  [6] INV — Invert input
    0=INPUT_NOT_INVERTED_; 1=INPUT_INVERTED_
  [4] MODE — Selects function mode (on-chip pull-up resistor control).
    values as PIO0_19.MODE
  [2:0] FUNC — Selects pin function. This pin functions as WAKEUP pin if the part is in Deep power-down mode regardless of the value of FUNC.
    0=SELECTS_FUNCTION_PIO (Selects function PIO1_3.); 1=AD5_ (Select function AD5.)
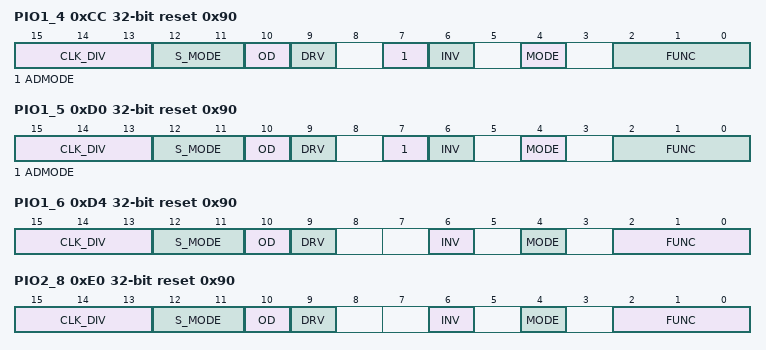
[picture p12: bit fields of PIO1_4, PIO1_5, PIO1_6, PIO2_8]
0xCC PIO1_4 reset 0x90 — Configures pin PIO1_4/AD6
  [15:13] CLK_DIV — Select peripheral clock divider for input filter sampling clock.
    {v}=IOCONFIGCLKDIV{v}_ (v=0..6)
  [12:11] S_MODE — Sample mode
    values as PIO0_19.S_MODE
  [10] OD — Open-drain mode.
    values as PIO0_19.OD
  [9] DRV — Drive current mode (Normal-drive pin).
    values as PIO0_27.DRV
  [7] ADMODE — Analog/Digital mode
    0=ANALOG_MODE_ENABLED_; 1=DIGITAL_MODE_ENABLED
  [6] INV — Invert input
    0=INPUT_NOT_INVERTED_; 1=INPUT_INVERTED_
  [4] MODE — Selects function mode (on-chip pull-up resistor control).
    values as PIO0_19.MODE
  [2:0] FUNC — Selects pin function.
    0=SELECTS_FUNCTION_PIO (Selects function PIO1_4.); 1=AD6_ (Select function AD6.)
0xD0 PIO1_5 reset 0x90 — Configures pin PIO1_5/AD7/CT16B1_0.
  [15:13] CLK_DIV — Select peripheral clock divider for input filter sampling clock.
    {v}=IOCONFIGCLKDIV{v}_ (v=0..6)
  [12:11] S_MODE — Sample mode
    values as PIO0_19.S_MODE
  [10] OD — Open-drain mode.
    values as PIO0_19.OD
  [9] DRV — Drive current mode (Normal-drive pin).
    0=LOW_MODE_DRIVE_CURRE (Low mode drive current selected.); 1=HIGH_MODE_CURRENT_SE (High mode current selected.)
  [7] ADMODE — Analog/Digital mode
    0=ANALOG_MODE_ENABLED_; 1=DIGITAL_MODE_ENABLED
  [6] INV — Invert input
    0=INPUT_NOT_INVERTED_; 1=INPUT_INVERTED_
  [4] MODE — Selects function mode (on-chip pull-up resistor control).
    values as PIO0_19.MODE
  [2:0] FUNC — Selects pin function.
    0=SELECTS_FUNCTION_PIO (Selects function PIO1_5.); 1=AD7_ (Select function AD7.); 2=CT16 (Select function CT16B1_CAP0.); 3=CT16 (Select function CT16B1_MAT0.)
0xD4 PIO1_6 reset 0x90 — Configures pin PIO1_6/CT16B1_1.
  [15:13] CLK_DIV — Select peripheral clock divider for input filter sampling clock.
    {v}=IOCONFIGCLKDIV{v}_ (v=0..6)
  [12:11] S_MODE — Sample mode
    values as PIO0_19.S_MODE
  [10] OD — Open-drain mode.
    values as PIO0_19.OD
  [9] DRV — Drive current mode (Normal-drive pin).
    values as PIO1_5.DRV
  [6] INV — Invert input
    0=INPUT_NOT_INVERTED_; 1=INPUT_INVERTED_
  [4] MODE — Selects function mode (on-chip pull-up resistor control).
    values as PIO0_19.MODE
  [2:0] FUNC — Selects pin function.
    0=SELECTS_FUNCTION_PIO (Selects function PIO1_6.); 1=CT16 (Select function CT16B1_CAP1.); 2=CT16 (Select function CT16B1_MAT1.)
0xE0 PIO2_8 reset 0x90 — Configures pin PIO2_8/CT32B1_0.
  [15:13] CLK_DIV — Select peripheral clock divider for input filter sampling clock.
    {v}=IOCONFIGCLKDIV{v}_ (v=0..6)
  [12:11] S_MODE — Sample mode
    values as PIO0_19.S_MODE
  [10] OD — Open-drain mode.
    values as PIO0_19.OD
  [9] DRV — Drive current mode (Normal-drive pin).
    values as PIO0_27.DRV
  [6] INV — Invert input
    0=INPUT_NOT_INVERTED_; 1=INPUT_INVERTED_
  [4] MODE — Selects function mode (on-chip pull-up resistor control).
    values as PIO0_19.MODE
  [2:0] FUNC — Selects pin function.
    0=SELECTS_FUNCTION_PIO (Selects function PIO2_8.); 1=RESERVED_DO_NOT_USE; 2=CT32 (Select function CT32B1_CAP0.); 3=CT32 (Select function CT32B1_MAT0.)
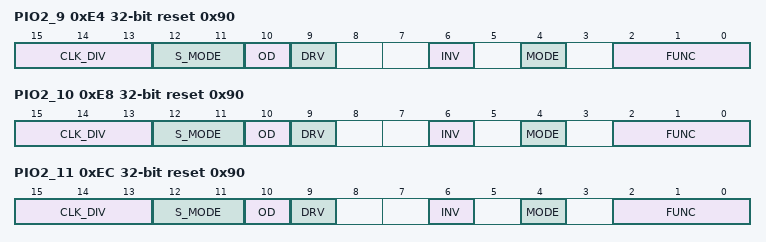
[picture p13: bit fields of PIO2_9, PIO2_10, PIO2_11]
0xE4 PIO2_9 reset 0x90 — Configures pin PIO2_9/CT32B1_1.
  [15:13] CLK_DIV — Select peripheral clock divider for input filter sampling clock.
    {v}=IOCONFIGCLKDIV{v}_ (v=0..6)
  [12:11] S_MODE — Sample mode
    values as PIO0_19.S_MODE
  [10] OD — Open-drain mode.
    values as PIO0_19.OD
  [9] DRV — Drive current mode (Normal-drive pin).
    values as PIO0_27.DRV
  [6] INV — Invert input
    0=INPUT_NOT_INVERTED_; 1=INPUT_INVERTED_
  [4] MODE — Selects function mode (on-chip pull-up resistor control).
    values as PIO0_19.MODE
  [2:0] FUNC — Selects pin function.
    0=SELECTS_FUNCTION_PIO (Selects function PIO2_9.); 1=RESERVED_DO_NOT_USE; 2=CT32 (Select function CT32B1_CAP1.); 3=CT32 (Select function CT32B1_MAT1.)
0xE8 PIO2_10 reset 0x90 — Configures pin PIO2_10/CT32B1_2/TXD1.
  [15:13] CLK_DIV — Select peripheral clock divider for input filter sampling clock.
    {v}=IOCONFIGCLKDIV{v}_ (v=0..6)
  [12:11] S_MODE — Sample mode
    values as PIO0_19.S_MODE
  [10] OD — Open-drain mode.
    values as PIO0_19.OD
  [9] DRV — Drive current mode (Normal-drive pin).
    values as PIO0_27.DRV
  [6] INV — Invert input
    0=INPUT_NOT_INVERTED_; 1=INPUT_INVERTED_
  [4] MODE — Selects function mode (on-chip pull-up resistor control).
    values as PIO0_19.MODE
  [2:0] FUNC — Selects pin function.
    0=SELECTS_FUNCTION_PIO (Selects function PIO2_10.); 1=RESERVED_DO_NOT_USE; 2=CT32 (Select function CT32B1_CAP2.); 3=CT32 (Select function CT32B1_MAT2.); 5=TXD1 (Select function TXD1.)
0xEC PIO2_11 reset 0x90 — Configures pin PIO2_11/CT32B1_3/RXD1.
  [15:13] CLK_DIV — Select peripheral clock divider for input filter sampling clock.
    {v}=IOCONFIGCLKDIV{v}_ (v=0..6)
  [12:11] S_MODE — Sample mode
    values as PIO0_19.S_MODE
  [10] OD — Open-drain mode.
    values as PIO0_19.OD
  [9] DRV — Drive current mode (Normal-drive pin).
    values as PIO0_27.DRV
  [6] INV — Invert input
    0=INPUT_NOT_INVERTED_; 1=INPUT_INVERTED_
  [4] MODE — Selects function mode (on-chip pull-up resistor control).
    values as PIO0_19.MODE
  [2:0] FUNC — Selects pin function.
    0=SELECTS_FUNCTION_PIO (Selects function PIO2_11.); 1=RESERVED_DO_NOT_USE; 2=CT32 (Select function CT32B1_CAP3.); 3=CT32 (Select function CT32B1_MAT3.); 5=RXD1 (Select function RXD1.)
